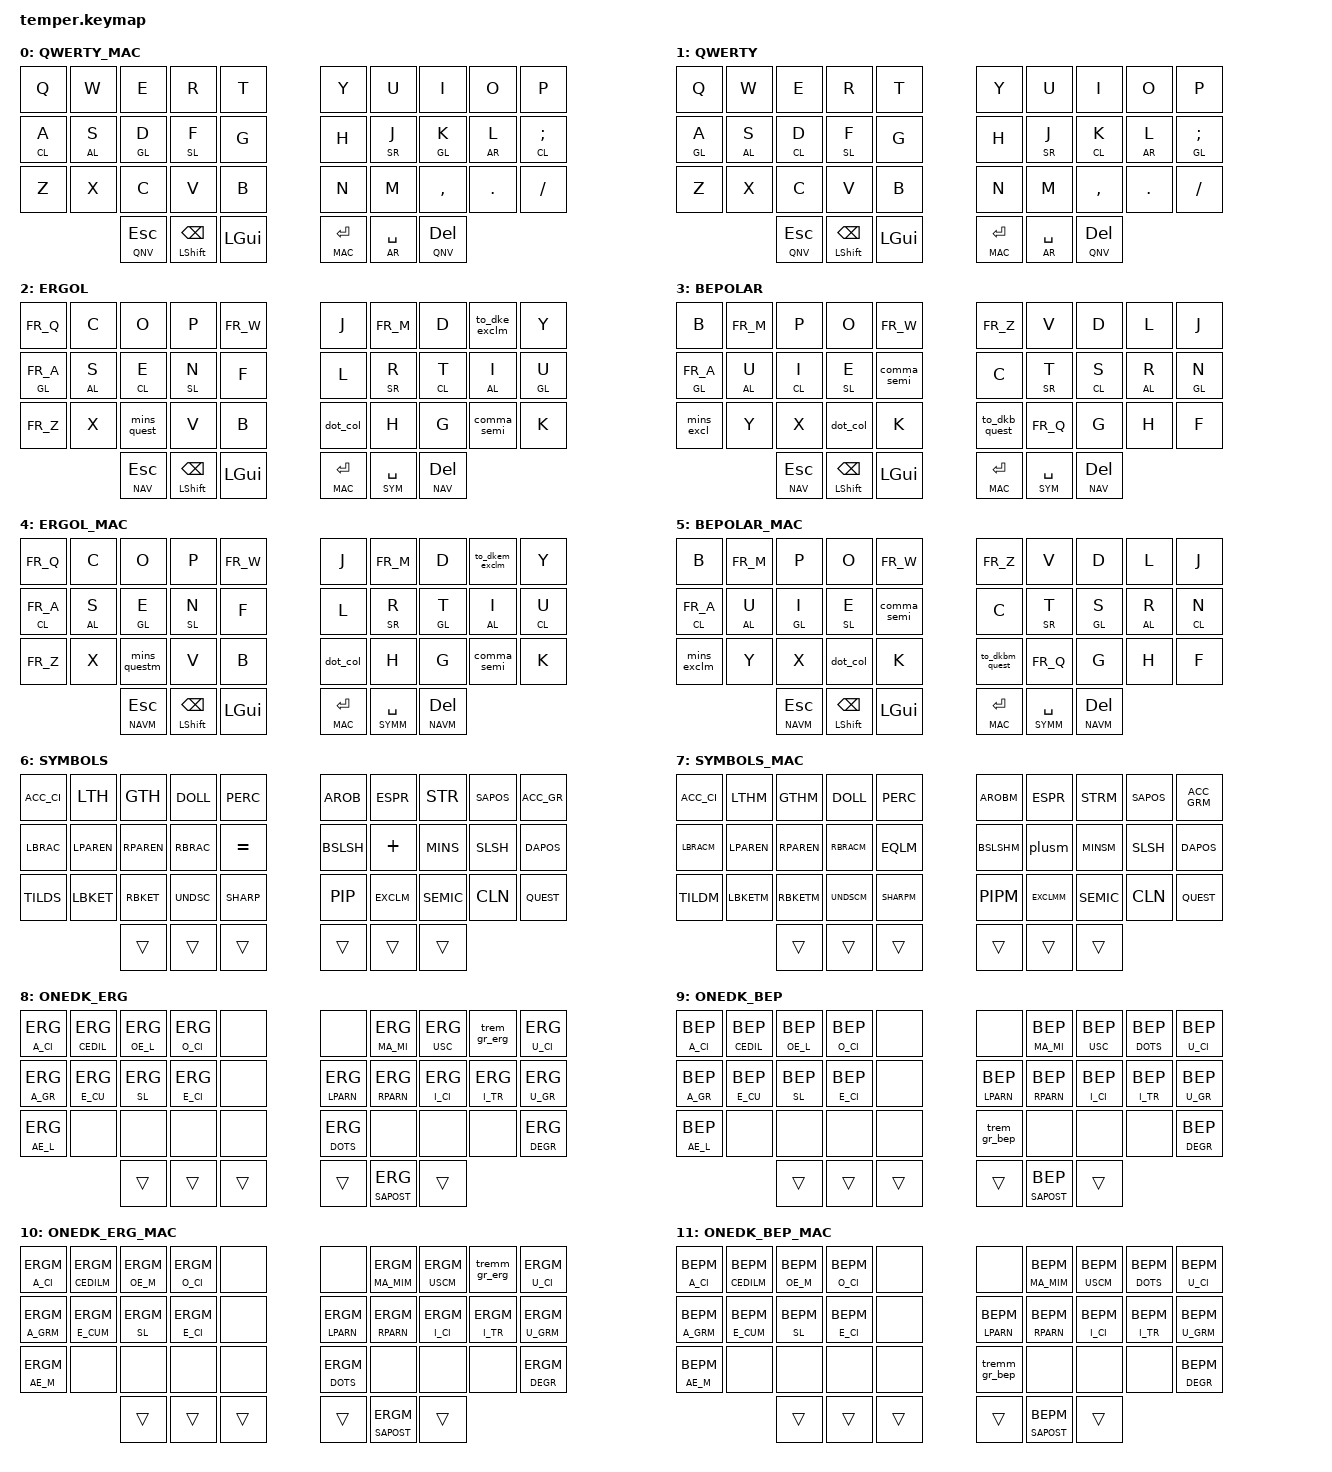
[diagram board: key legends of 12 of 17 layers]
/*
 * Copyright (c) 2020 The ZMK Contributors
 *
 * SPDX-License-Identifier: MIT
 */

#include <behaviors.dtsi>

#include <dt-bindings/zmk/keys.h>
#include <dt-bindings/zmk/bt.h>
#include <dt-bindings/zmk/outputs.h>

#include "constants.h"
#define HOST_OS MAC_OS // Needed for unicode international_chars

#include "zmk-helpers/helper.h"
#include "zmk-helpers/key-labels/36.h"
#include "layouts/french.dtsi"
#include "behaviors/soft-off.dtsi"
#include "behaviors/hold-tap.dtsi"
#include "behaviors/macros.dtsi"
#include "behaviors/mod-morph.dtsi"

&mt {
    quick-tap-ms = <300>;
};

ZMK_CONDITIONAL_LAYER(TRILAYERNAV,  NAV  MAC, ADJ)
ZMK_CONDITIONAL_LAYER(TRILAYERNAVM, NAVM MAC, ADJ)
ZMK_CONDITIONAL_LAYER(TRILAYERQWE,  QNV  MAC, ADJ)


ZMK_LAYER(QWERTY_MAC,
// ╭─────────────┬─────────────┬─────────────┬─────────────┬─────────────╮   ╭─────────────┬─────────────┬─────────────┬─────────────┬─────────────╮
         &kp Q        &kp W         &kp E         &kp R         &kp T             &kp Y         &kp U         &kp I         &kp O         &kp P
// ├─────────────┼─────────────┼─────────────┼─────────────┼─────────────┤   ├─────────────┼─────────────┼─────────────┼─────────────┼─────────────┤
       &hml CL A    &hml AL S     &hml GL D     &hml SL F       &kp G             &kp H       &hmr SR J     &hmr GL K     &hmr AR L   &hmr CL SEMI
// ├─────────────┼─────────────┼─────────────┼─────────────┼─────────────┤   ├─────────────┼─────────────┼─────────────┼─────────────┼─────────────┤
         &kp Z        &kp X         &kp C         &kp V         &kp B             &kp N         &kp M       &kp COMMA      &kp DOT      &kp SLASH
// ╰─────────────┴─────────────┼─────────────┼─────────────┼─────────────┤   ├─────────────┼─────────────┼─────────────┼─────────────┴─────────────╯
                                 &lt QNV ESC  &mt LSHFT BSPC  &kp LGUI         &lt MAC RET   &mt AR SPACE  &lt QNV DEL 
//                             ╰─────────────┴─────────────┴─────────────╯   ╰─────────────┴─────────────┴─────────────╯
)

ZMK_LAYER(QWERTY,
// ╭─────────────┬─────────────┬─────────────┬─────────────┬─────────────╮   ╭─────────────┬─────────────┬─────────────┬─────────────┬─────────────╮
         &kp Q        &kp W         &kp E         &kp R         &kp T             &kp Y         &kp U         &kp I         &kp O         &kp P
// ├─────────────┼─────────────┼─────────────┼─────────────┼─────────────┤   ├─────────────┼─────────────┼─────────────┼─────────────┼─────────────┤
       &hml GL A    &hml AL S     &hml CL D     &hml SL F       &kp G             &kp H       &hmr SR J     &hmr CL K     &hmr AR L   &hmr GL SEMI
// ├─────────────┼─────────────┼─────────────┼─────────────┼─────────────┤   ├─────────────┼─────────────┼─────────────┼─────────────┼─────────────┤
         &kp Z        &kp X         &kp C         &kp V         &kp B             &kp N         &kp M       &kp COMMA      &kp DOT      &kp SLASH
// ╰─────────────┴─────────────┼─────────────┼─────────────┼─────────────┤   ├─────────────┼─────────────┼─────────────┼─────────────┴─────────────╯
                                 &lt QNV ESC  &mt LSHFT BSPC  &kp LGUI         &lt MAC RET   &mt AR SPACE  &lt QNV DEL 
//                             ╰─────────────┴─────────────┴─────────────╯   ╰─────────────┴─────────────┴─────────────╯
)

ZMK_LAYER(ERGOL,
// ╭─────────────┬─────────────┬─────────────┬─────────────┬─────────────╮   ╭─────────────┬─────────────┬─────────────┬─────────────┬─────────────╮
       &kp FR_Q       &kp C         &kp O         &kp P        &kp FR_W            &kp J       &kp FR_M       &kp D     &to_dke_exclm     &kp Y
// ├─────────────┼─────────────┼─────────────┼─────────────┼─────────────┤   ├─────────────┼─────────────┼─────────────┼─────────────┼─────────────┤
     &hml GL FR_A   &hml AL S     &hml CL E     &hml SL N       &kp F              &kp L       &hmr SR R     &hmr CL T     &hmr AL I    &hmr GL U
// ├─────────────┼─────────────┼─────────────┼─────────────┼─────────────┤   ├─────────────┼─────────────┼─────────────┼─────────────┼─────────────┤
       &kp FR_Z       &kp X      &mins_quest      &kp V         &kp B            &dot_col        &kp H         &kp G     &comma_semi      &kp K
// ╰─────────────┴─────────────┼─────────────┼─────────────┼─────────────┤   ├─────────────┼─────────────┼─────────────┼─────────────┴─────────────╯
                                 &lt NAV ESC  &mt LSHFT BSPC  &kp LGUI         &lt MAC RET  &lt SYM SPACE  &lt NAV DEL    
//                             ╰─────────────┴─────────────┴─────────────╯   ╰─────────────┴─────────────┴─────────────╯
)

ZMK_LAYER(BEPOLAR,
// ╭─────────────┬─────────────┬─────────────┬─────────────┬─────────────╮   ╭─────────────┬─────────────┬─────────────┬─────────────┬─────────────╮
        &kp B        &kp FR_M       &kp P         &kp O        &kp FR_W          &kp FR_Z       &kp V         &kp D         &kp L         &kp J      
// ├─────────────┼─────────────┼─────────────┼─────────────┼─────────────┤   ├─────────────┼─────────────┼─────────────┼─────────────┼─────────────┤
    &hml GL FR_A    &hml AL U     &hml CL I     &hml SL E    &comma_semi          &kp C       &hmr SR T     &hmr CL S     &hmr AL R     &hmr GL N
// ├─────────────┼─────────────┼─────────────┼─────────────┼─────────────┤   ├─────────────┼─────────────┼─────────────┼─────────────┼─────────────┤
      &mins_excl      &kp Y          &kp X       &dot_col       &kp K         &to_dkb_quest    &kp FR_Q       &kp G         &kp H         &kp F
// ╰─────────────┴─────────────┼─────────────┼─────────────┼─────────────┤   ├─────────────┼─────────────┼─────────────┼─────────────┴─────────────╯
                                 &lt NAV ESC  &mt LSHFT BSPC  &kp LGUI         &lt MAC RET  &lt SYM SPACE  &lt NAV DEL
//                             ╰─────────────┴─────────────┴─────────────╯   ╰─────────────┴─────────────┴─────────────╯
)

ZMK_LAYER(ERGOL_MAC,
// ╭─────────────┬─────────────┬─────────────┬─────────────┬─────────────╮   ╭─────────────┬─────────────┬─────────────┬─────────────┬─────────────╮
       &kp FR_Q       &kp C         &kp O         &kp P        &kp FR_W            &kp J       &kp FR_M       &kp D     &to_dkem_exclm    &kp Y
// ├─────────────┼─────────────┼─────────────┼─────────────┼─────────────┤   ├─────────────┼─────────────┼─────────────┼─────────────┼─────────────┤
     &hml CL FR_A   &hml AL S     &hml GL E     &hml SL N       &kp F              &kp L       &hmr SR R     &hmr GL T     &hmr AL I    &hmr CL U
// ├─────────────┼─────────────┼─────────────┼─────────────┼─────────────┤   ├─────────────┼─────────────┼─────────────┼─────────────┼─────────────┤
       &kp FR_Z       &kp X      &mins_questm     &kp V         &kp B            &dot_col        &kp H         &kp G     &comma_semi      &kp K
// ╰─────────────┴─────────────┼─────────────┼─────────────┼─────────────┤   ├─────────────┼─────────────┼─────────────┼─────────────┴─────────────╯
                                &lt NAVM ESC  &mt LSHFT BSPC  &kp LGUI         &lt MAC RET  &lt SYMM SPACE  &lt NAVM DEL    
//                             ╰─────────────┴─────────────┴─────────────╯   ╰─────────────┴─────────────┴─────────────╯
)

ZMK_LAYER(BEPOLAR_MAC,
// ╭─────────────┬─────────────┬─────────────┬─────────────┬─────────────╮   ╭─────────────┬─────────────┬─────────────┬─────────────┬─────────────╮
        &kp B        &kp FR_M       &kp P         &kp O        &kp FR_W          &kp FR_Z       &kp V         &kp D         &kp L         &kp J      
// ├─────────────┼─────────────┼─────────────┼─────────────┼─────────────┤   ├─────────────┼─────────────┼─────────────┼─────────────┼─────────────┤
    &hml CL FR_A    &hml AL U     &hml GL I     &hml SL E    &comma_semi          &kp C       &hmr SR T     &hmr GL S     &hmr AL R     &hmr CL N
// ├─────────────┼─────────────┼─────────────┼─────────────┼─────────────┤   ├─────────────┼─────────────┼─────────────┼─────────────┼─────────────┤
     &mins_exclm      &kp Y          &kp X       &dot_col       &kp K         &to_dkbm_quest   &kp FR_Q       &kp G         &kp H         &kp F
// ╰─────────────┴─────────────┼─────────────┼─────────────┼─────────────┤   ├─────────────┼─────────────┼─────────────┼─────────────┴─────────────╯
                                &lt NAVM ESC  &mt LSHFT BSPC  &kp LGUI         &lt MAC RET  &lt SYMM SPACE  &lt NAVM DEL
//                             ╰─────────────┴─────────────┴─────────────╯   ╰─────────────┴─────────────┴─────────────╯
)

ZMK_LAYER(SYMBOLS,
// ╭─────────────┬─────────────┬─────────────┬─────────────┬─────────────╮   ╭─────────────┬─────────────┬─────────────┬─────────────┬─────────────╮
      &kp ACC_CI     &kp LTH       &kp GTH       &kp DOLL     &kp PERC           &kp AROB      &kp ESPR      &kp STR       &kp SAPOS    &kp ACC_GR
// ├─────────────┼─────────────┼─────────────┼─────────────┼─────────────┤   ├─────────────┼─────────────┼─────────────┼─────────────┼─────────────┤
      &kp LBRAC    &kp LPAREN    &kp RPAREN     &kp RBRAC     &kp EQUAL          &kp BSLSH     &kp PLUS      &kp MINS      &kp SLSH     &kp DAPOS
// ├─────────────┼─────────────┼─────────────┼─────────────┼─────────────┤   ├─────────────┼─────────────┼─────────────┼─────────────┼─────────────┤
      &kp TILDS     &kp LBKET      &kp RBKET    &kp UNDSC     &kp SHARP          &kp PIP       &kp EXCLM     &kp SEMIC     &kp CLN      &kp QUEST
// ╰─────────────┴─────────────┼─────────────┼─────────────┼─────────────┤   ├─────────────┼─────────────┼─────────────┼─────────────┴─────────────╯
                                    &trans        &trans        &trans            &trans        &trans        &trans
//                             ╰─────────────┴─────────────┴─────────────╯   ╰─────────────┴─────────────┴─────────────╯
)

ZMK_LAYER(SYMBOLS_MAC,
// ╭─────────────┬─────────────┬─────────────┬─────────────┬─────────────╮   ╭─────────────┬─────────────┬─────────────┬─────────────┬─────────────╮
      &kp ACC_CI    &kp LTHM      &kp GTHM       &kp DOLL      &kp PERC          &kp AROBM     &kp ESPR      &kp STRM     &kp SAPOS    &kp ACC_GRM
// ├─────────────┼─────────────┼─────────────┼─────────────┼─────────────┤   ├─────────────┼─────────────┼─────────────┼─────────────┼─────────────┤
      &kp LBRACM    &kp LPAREN    &kp RPAREN    &kp RBRACM     &kp EQLM         &kp BSLSHM     &plusm       &kp MINSM      &kp SLSH     &kp DAPOS
// ├─────────────┼─────────────┼─────────────┼─────────────┼─────────────┤   ├─────────────┼─────────────┼─────────────┼─────────────┼─────────────┤
      &kp TILDM     &kp LBKETM    &kp RBKETM    &kp UNDSCM    &kp SHARPM         &kp PIPM     &kp EXCLMM    &kp SEMIC      &kp CLN      &kp QUEST
// ╰─────────────┴─────────────┼─────────────┼─────────────┼─────────────┤   ├─────────────┼─────────────┼─────────────┼─────────────┴─────────────╯
                                    &trans        &trans        &trans            &trans        &trans        &trans
//                             ╰─────────────┴─────────────┴─────────────╯   ╰─────────────┴─────────────┴─────────────╯
)

ZMK_LAYER(ONEDK_ERG,
// ╭─────────────┬─────────────┬─────────────┬─────────────┬─────────────╮   ╭─────────────┬─────────────┬─────────────┬─────────────┬─────────────╮
      &A_CI ERG     &CEDIL ERG    &OE_L ERG     &O_CI ERG       &none             &none      &MA_MI ERG      &USC ERG   &trem_gr_erg    &U_CI ERG
// ├─────────────┼─────────────┼─────────────┼─────────────┼─────────────┤   ├─────────────┼─────────────┼─────────────┼─────────────┼─────────────┤
      &A_GR ERG     &E_CU ERG   &hrmec SL ERG   &E_CI ERG       &none           &LPARN ERG    &RPARN ERG     &I_CI ERG    &I_TR ERG     &U_GR ERG
// ├─────────────┼─────────────┼─────────────┼─────────────┼─────────────┤   ├─────────────┼─────────────┼─────────────┼─────────────┼─────────────┤
      &AE_L ERG       &none         &none         &none         &none           &DOTS ERG       &none         &none         &none       &DEGR ERG
// ╰─────────────┴─────────────┼─────────────┼─────────────┼─────────────┤   ├─────────────┼─────────────┼─────────────┼─────────────┴─────────────╯
                                    &trans        &trans        &trans            &trans     &SAPOST ERG     &trans
//                             ╰─────────────┴─────────────┴─────────────╯   ╰─────────────┴─────────────┴─────────────╯
)

ZMK_LAYER(ONEDK_BEP,
// ╭─────────────┬─────────────┬─────────────┬─────────────┬─────────────╮   ╭─────────────┬─────────────┬─────────────┬─────────────┬─────────────╮
      &A_CI BEP     &CEDIL BEP    &OE_L BEP     &O_CI BEP       &none             &none      &MA_MI BEP      &USC BEP     &DOTS BEP     &U_CI BEP
// ├─────────────┼─────────────┼─────────────┼─────────────┼─────────────┤   ├─────────────┼─────────────┼─────────────┼─────────────┼─────────────┤
      &A_GR BEP     &E_CU BEP   &hrmeb SL BEP   &E_CI BEP       &none           &LPARN BEP    &RPARN BEP     &I_CI BEP    &I_TR BEP     &U_GR BEP
// ├─────────────┼─────────────┼─────────────┼─────────────┼─────────────┤   ├─────────────┼─────────────┼─────────────┼─────────────┼─────────────┤
      &AE_L BEP       &none         &none         &none         &none         &trem_gr_bep      &none         &none         &none       &DEGR BEP
// ╰─────────────┴─────────────┼─────────────┼─────────────┼─────────────┤   ├─────────────┼─────────────┼─────────────┼─────────────┴─────────────╯
                                    &trans        &trans        &trans            &trans     &SAPOST BEP     &trans
//                             ╰─────────────┴─────────────┴─────────────╯   ╰─────────────┴─────────────┴─────────────╯
)

ZMK_LAYER(ONEDK_ERG_MAC,
// ╭─────────────┬─────────────┬─────────────┬─────────────┬─────────────╮   ╭─────────────┬─────────────┬─────────────┬─────────────┬─────────────╮
      &A_CI ERGM   &CEDILM ERGM   &OE_M ERGM   &O_CI ERGM       &none             &none      &MA_MIM ERGM   &USCM ERGM   &tremm_gr_erg   &U_CI ERGM
// ├─────────────┼─────────────┼─────────────┼─────────────┼─────────────┤   ├─────────────┼─────────────┼─────────────┼─────────────┼─────────────┤
     &A_GRM ERGM   &E_CUM ERGM &hrmecm SL ERGM  &E_CI ERGM      &none          &LPARN ERGM    &RPARN ERGM   &I_CI ERGM    &I_TR ERGM    &U_GRM ERGM
// ├─────────────┼─────────────┼─────────────┼─────────────┼─────────────┤   ├─────────────┼─────────────┼─────────────┼─────────────┼─────────────┤
      &AE_M ERGM      &none         &none         &none         &none           &DOTS ERGM      &none         &none         &none       &DEGR ERGM
// ╰─────────────┴─────────────┼─────────────┼─────────────┼─────────────┤   ├─────────────┼─────────────┼─────────────┼─────────────┴─────────────╯
                                    &trans        &trans        &trans            &trans     &SAPOST ERGM     &trans
//                             ╰─────────────┴─────────────┴─────────────╯   ╰─────────────┴─────────────┴─────────────╯
)

ZMK_LAYER(ONEDK_BEP_MAC,
// ╭─────────────┬─────────────┬─────────────┬─────────────┬─────────────╮   ╭─────────────┬─────────────┬─────────────┬─────────────┬─────────────╮
      &A_CI BEPM   &CEDILM BEPM   &OE_M BEPM    &O_CI BEPM      &none             &none      &MA_MIM BEPM   &USCM BEPM    &DOTS BEPM   &U_CI BEPM
// ├─────────────┼─────────────┼─────────────┼─────────────┼─────────────┤   ├─────────────┼─────────────┼─────────────┼─────────────┼─────────────┤
     &A_GRM BEPM   &E_CUM BEPM &hrmebm SL BEPM  &E_CI BEPM      &none           &LPARN BEPM   &RPARN BEPM   &I_CI BEPM    &I_TR BEPM   &U_GRM BEPM
// ├─────────────┼─────────────┼─────────────┼─────────────┼─────────────┤   ├─────────────┼─────────────┼─────────────┼─────────────┼─────────────┤
      &AE_M BEPM      &none         &none         &none         &none         &tremm_gr_bep     &none         &none         &none      &DEGR BEPM
// ╰─────────────┴─────────────┼─────────────┼─────────────┼─────────────┤   ├─────────────┼─────────────┼─────────────┼─────────────┴─────────────╯
                                    &trans        &trans        &trans            &trans     &SAPOST BEPM     &trans
//                             ╰─────────────┴─────────────┴─────────────╯   ╰─────────────┴─────────────┴─────────────╯
)

ZMK_LAYER(NAV,
// ╭─────────────┬─────────────┬─────────────┬─────────────┬─────────────╮   ╭─────────────┬─────────────┬─────────────┬─────────────┬─────────────╮
        &none        &kp HOME       &kp UP       &kp END      &kp PG_UP          &kp SLSH     &FR_7_ESPR    &FR_8_STR    &FR_9_SHARP     &kp STR
// ├─────────────┼─────────────┼─────────────┼─────────────┼─────────────┤   ├─────────────┼─────────────┼─────────────┼─────────────┼─────────────┤
      &caps_word     &kp LEFT      &kp DOWN      &kp RIGHT    &kp PG_DN         &kp MINSM     &FR_4_DOLL   &FR_5_PERC    &FR_6_CIRC    &FR_0_AROB
// ├─────────────┼─────────────┼─────────────┼─────────────┼─────────────┤   ├─────────────┼─────────────┼─────────────┼─────────────┼─────────────┤
        &none      &kp LS(TAB)      &none        &kp TAB        &none            &kp COMM     &FR_1_EURO   &FR_2_LAQUO   &FR_3_RAQUO     &kp PERD
// ╰─────────────┴─────────────┼─────────────┼─────────────┼─────────────┤   ├─────────────┼─────────────┼─────────────┼─────────────┴─────────────╯
                                    &trans        &trans        &trans            &trans      &kp NBSPC       &trans
//                             ╰─────────────┴─────────────┴─────────────╯   ╰─────────────┴─────────────┴─────────────╯
)

ZMK_LAYER(NAV_MAC,
// ╭─────────────┬─────────────┬─────────────┬─────────────┬─────────────╮   ╭─────────────┬─────────────┬─────────────┬─────────────┬─────────────╮
        &none        &kp HOME       &kp UP       &kp END      &kp PG_UP          &kp SLSH    &FR_7_ESPRM    &FR_8_STRM   &FR_9_SHARPM    &kp STRM
// ├─────────────┼─────────────┼─────────────┼─────────────┼─────────────┤   ├─────────────┼─────────────┼─────────────┼─────────────┼─────────────┤
      &caps_word     &kp LEFT      &kp DOWN      &kp RIGHT    &kp PG_DN         &kp MINSM    &FR_4_DOLLM   &FR_5_PERCM   &FR_6_CIRCM    &FR_0_AROBM
// ├─────────────┼─────────────┼─────────────┼─────────────┼─────────────┤   ├─────────────┼─────────────┼─────────────┼─────────────┼─────────────┤
        &none      &kp LS(TAB)      &none        &kp TAB        &none            &kp COMM    &FR_1_EUROM  &FR_2_LAQUOM   &FR_3_RAQUOM    &kp PERD
// ╰─────────────┴─────────────┼─────────────┼─────────────┼─────────────┤   ├─────────────┼─────────────┼─────────────┼─────────────┴─────────────╯
                                    &trans        &trans        &trans            &trans      &kp NBSPC      &trans
//                             ╰─────────────┴─────────────┴─────────────╯   ╰─────────────┴─────────────┴─────────────╯
)

ZMK_LAYER(QWERTY_NAV,
// ╭─────────────┬─────────────┬─────────────┬─────────────┬─────────────╮   ╭─────────────┬─────────────┬─────────────┬─────────────┬─────────────╮
        &none        &kp HOME       &kp UP       &kp END      &kp PG_UP         &kp MINUS       &kp N7        &kp N8        &kp N9      &kp RA(I)
// ├─────────────┼─────────────┼─────────────┼─────────────┼─────────────┤   ├─────────────┼─────────────┼─────────────┼─────────────┼─────────────┤
      &caps_word     &kp LEFT      &kp DOWN      &kp RIGHT    &kp PG_DN           &kp C         &kp N4        &kp N5        &kp N6       &kp N0
// ├─────────────┼─────────────┼─────────────┼─────────────┼─────────────┤   ├─────────────┼─────────────┼─────────────┼─────────────┼─────────────┤
        &none      &kp LS(TAB)      &none        &kp TAB        &none            &kp DOT        &kp N1        &kp N2        &kp N3       &kp N
// ╰─────────────┴─────────────┼─────────────┼─────────────┼─────────────┤   ├─────────────┼─────────────┼─────────────┼─────────────┴─────────────╯
                                    &trans        &trans        &trans            &trans      &kp NBSPC      &trans
//                             ╰─────────────┴─────────────┴─────────────╯   ╰─────────────┴─────────────┴─────────────╯
)

ZMK_LAYER(MACROS,
// ╭─────────────┬─────────────┬─────────────┬─────────────┬─────────────╮   ╭─────────────┬─────────────┬─────────────┬─────────────┬─────────────╮
     &kp C_VOL_UP  &kp C_BRI_UP     &trans        &trans      &kp C_PREV        &kp PSCRN       &kp F7        &kp F8        &kp F9       &kp F12
// ├─────────────┼─────────────┼─────────────┼─────────────┼─────────────┤   ├─────────────┼─────────────┼─────────────┼─────────────┼─────────────┤
     &kp K_MUTE   &kp C_BRI_AUTO    &trans        &trans       &kp C_PP           &trans        &kp F4        &kp F5        &kp F6       &kp F11
// ├─────────────┼─────────────┼─────────────┼─────────────┼─────────────┤   ├─────────────┼─────────────┼─────────────┼─────────────┼─────────────┤
     &kp C_VOL_DN  &kp C_BRI_DN     &trans        &trans      &kp C_NEXT          &trans        &kp F1        &kp F2        &kp F3       &kp F10
// ╰─────────────┴─────────────┼─────────────┼─────────────┼─────────────┤   ├─────────────┼─────────────┼─────────────┼─────────────┴─────────────╯
                                    &trans        &trans        &trans            &trans       &trans        &trans
//                             ╰─────────────┴─────────────┴─────────────╯   ╰─────────────┴─────────────┴─────────────╯
)

ZMK_LAYER(ADJUST,
// ╭─────────────┬─────────────┬─────────────┬─────────────┬─────────────╮   ╭─────────────┬─────────────┬─────────────┬─────────────┬─────────────╮
      &sys_reset   &bootloader &bt BT_CLR_ALL  &out OUT_USB  &out OUT_BLE        &trans        &trans        &trans      &bootloader    &sys_reset 
// ├─────────────┼─────────────┼─────────────┼─────────────┼─────────────┤   ├─────────────┼─────────────┼─────────────┼─────────────┼─────────────┤
     &bt BT_SEL 0  &bt BT_SEL 1  &bt BT_SEL 2  &bt BT_SEL 3  &bt BT_SEL 4        &trans        &trans        &trans        &trans        &trans
// ├─────────────┼─────────────┼─────────────┼─────────────┼─────────────┤   ├─────────────┼─────────────┼─────────────┼─────────────┼─────────────┤
      &bt BT_CLR     &to QWEM      &to QWE       &to ERG      &to ERGM          &soft_off      &trans        &trans        &trans        &trans
// ╰─────────────┴─────────────┼─────────────┼─────────────┼─────────────┤   ├─────────────┼─────────────┼─────────────┼─────────────┴─────────────╯
                                    &trans        &trans       &trans            &trans        &trans        &trans
//                             ╰─────────────┴─────────────┴─────────────╯   ╰─────────────┴─────────────┴─────────────╯
)
